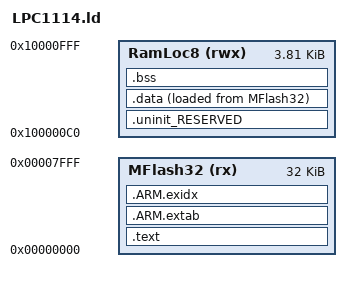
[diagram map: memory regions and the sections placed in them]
/* mbed - LPC1114 linker script
 * Based linker script generated by Code Red Technologies Red Suite 4.1
 */
GROUP(libgcc.a libc.a libstdc++.a libm.a libcr_newlib_nohost.a crti.o crtn.o crtbegin.o crtend.o)

MEMORY
{
  /* Define each memory region */
  MFlash32 (rx) : ORIGIN = 0x0, LENGTH = 0x8000 /* 32k */
  RamLoc8 (rwx) : ORIGIN = 0x100000C0, LENGTH = 0x0F40 /* 4k */
}
  /* Define a symbol for the top of each memory region */
  __top_MFlash32 = 0x0 + 0x8000;
  __top_RamLoc8 = 0x10000000 + 0x0F40;

ENTRY(ResetISR)

SECTIONS
{

    /* MAIN TEXT SECTION */ 
    .text : ALIGN(8)
    {
        FILL(0xff)
        KEEP(*(.isr_vector))
		*(.text.ResetISR)
        *(.text.SystemInit)
		. = 0x200;
        
        /* Global Section Table */
        . = ALIGN(8) ;
        __section_table_start = .;
        __data_section_table = .;
        LONG(LOADADDR(.data));
        LONG(    ADDR(.data)) ;
        LONG(  SIZEOF(.data));
        __data_section_table_end = .;
        __bss_section_table = .;
        LONG(    ADDR(.bss));
        LONG(  SIZEOF(.bss));
        __bss_section_table_end = .;
        __section_table_end = . ;
        /* End of Global Section Table */
        

        *(.after_vectors*)
        
        *(.text*)
        *(.rodata .rodata.*)
        . = ALIGN(8);
        
        /* C++ constructors etc */
        . = ALIGN(8);
        KEEP(*(.init))
        
        . = ALIGN(8);
        __preinit_array_start = .;
        KEEP (*(.preinit_array))
        __preinit_array_end = .;
        
        . = ALIGN(8);
        __init_array_start = .;
        KEEP (*(SORT(.init_array.*)))
        KEEP (*(.init_array))
        __init_array_end = .;
        
        KEEP(*(.fini));
        
        . = ALIGN(0x4);
        KEEP (*crtbegin.o(.ctors))
        KEEP (*(EXCLUDE_FILE (*crtend.o) .ctors))
        KEEP (*(SORT(.ctors.*)))
        KEEP (*crtend.o(.ctors))
        
        . = ALIGN(0x4);
        KEEP (*crtbegin.o(.dtors))
        KEEP (*(EXCLUDE_FILE (*crtend.o) .dtors))
        KEEP (*(SORT(.dtors.*)))
        KEEP (*crtend.o(.dtors))
        /* End C++ */
    } > MFlash32

    /*
     * for exception handling/unwind - some Newlib functions (in common
     * with C++ and STDC++) use this.
     */
    .ARM.extab : ALIGN(8)
    {
        *(.ARM.extab* .gnu.linkonce.armextab.*)
    } > MFlash32
    __exidx_start = .;
    
    .ARM.exidx : ALIGN(8)
    {
        *(.ARM.exidx* .gnu.linkonce.armexidx.*)
    } > MFlash32
    __exidx_end = .;
    
    _etext = .;
        
    
    
    /* MAIN DATA SECTION */

    .uninit_RESERVED : ALIGN(8)
    {
        KEEP(*(.bss.$RESERVED*))
    } > RamLoc8

    .data : ALIGN(8)
    {
        FILL(0xff)
        _data = .;
        *(vtable)
        *(.data*)
        . = ALIGN(8) ;
        _edata = .;
    } > RamLoc8 AT>MFlash32

    

    /* MAIN BSS SECTION */
    .bss : ALIGN(8)
    {
        _bss = .;
        *(.bss*)
        *(COMMON)
        . = ALIGN(8) ;
        _ebss = .;
        PROVIDE(end = .);
        __end__ = .;
    } > RamLoc8
    
    PROVIDE(_pvHeapStart = .);
    PROVIDE(_vStackTop = __top_RamLoc8 - 0);
}
